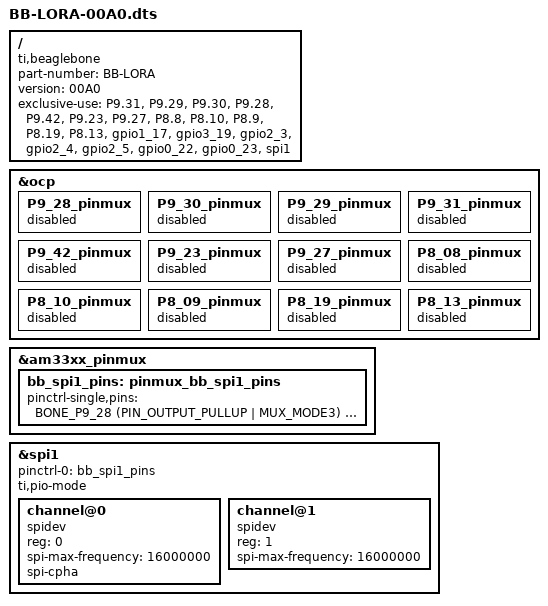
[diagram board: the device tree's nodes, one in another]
/*
 * 2018 Copyright (c) Seeed Technology Inc.  All right reserved.
 * Author:Junmin Fan <junmin.fan@seeed.cc>
 *
 * This program is free software; you can redistribute it and/or modify
 * it under the terms of the GNU General Public License version 2 as
 * published by the Free Software Foundation.
 */

/dts-v1/;
/plugin/;

#include <dt-bindings/board/am335x-bbw-bbb-base.h>
#include <dt-bindings/pinctrl/am33xx.h>

/ {
	compatible = "ti,beaglebone", "ti,beaglebone-black", "ti,beaglebone-green";

	/* identification */
	part-number = "BB-LORA";
	version = "00A0";

	/* state the resources this cape uses */
	exclusive-use =
		/* the pin header uses */
		"P9.31",	/* spi1_sclk */
		"P9.29",	/* spi1_d0 */
		"P9.30",	/* spi1_d1 */
		"P9.28",	/* spi1_cs0 */
		"P9.42",	/* spi1_cs1 */
		"P9.23",	/* lora reset gpio1_17 */
		"P9.27",	/* lora GPIO0 gpio3_19 */
		"P8.8",	    /* lora GPIO1 gpio2_3 */
		"P8.10",	/* lora GPIO2 gpio2_4 */
		"P8.9",	    /* lora GPIO3 gpio2_5 */
		"P8.19",	/* lora GPIO4 gpio0_22 */
		"P8.13",	/* lora GPS_PPS gpio0_23 */

		/* the hardware ip uses */
		"gpio1_17",
		"gpio3_19",
		"gpio2_3",
		"gpio2_4",
		"gpio2_5",
		"gpio0_22",
		"gpio0_23",
		"spi1";

	/*
	 * Free up the pins used by the cape from the pinmux helpers.
	 */
	fragment@0 {
		target = <&ocp>;
		__overlay__ {
			P9_28_pinmux { status = "disabled"; };	/* spi1_cs0 */
			P9_30_pinmux { status = "disabled"; };	/* spi1_d1 */
			P9_29_pinmux { status = "disabled"; };	/* spi1_d0 */
			P9_31_pinmux { status = "disabled"; };	/* spi1_sclk */
			P9_42_pinmux { status = "disabled"; };	/* spi1_cs1 */
			P9_23_pinmux { status = "disabled"; };	/* lora reset gpio1_17 */
			P9_27_pinmux { status = "disabled"; };	/* lora GPIO0 gpio3_19 */
			P8_08_pinmux { status = "disabled"; };	/* lora GPIO1 gpio2_3 */
			P8_10_pinmux { status = "disabled"; };	/* lora GPIO2 gpio2_4 */
			P8_09_pinmux { status = "disabled"; };	/* lora GPIO3 gpio2_5 */
			P8_19_pinmux { status = "disabled"; };	/* lora GPIO4 gpio0_22 */
			P8_13_pinmux { status = "disabled"; };	/* lora GPS_PPS gpio0_23 */
		};
	};

	fragment@1 {
		target = <&am33xx_pinmux>;
		__overlay__ {
			/* default state has all gpios released and mode set to uart1 */
			bb_spi1_pins: pinmux_bb_spi1_pins {
				pinctrl-single,pins = <
					BONE_P9_28 (PIN_OUTPUT_PULLUP | MUX_MODE3)	 /* mcasp0_ahclkr.spi1_cs0, OUTPUT_PULLUP | MODE3  */
					BONE_P9_30 (PIN_OUTPUT_PULLUP | MUX_MODE3)	 /* mcasp0_axr0.spi1_d1, OUTPUT_PULLUP | MODE3  */
					BONE_P9_29 (PIN_INPUT_PULLUP | MUX_MODE3)	 /* mcasp0_fsx.spi1_d0, INPUT_PULLUP | MODE3  */
					BONE_P9_31 (PIN_INPUT_PULLUP | MUX_MODE3)	 /* mcasp0_aclkx.spi1_sclk, INPUT_PULLUP | MODE3  */
					BONE_P9_23 (PIN_OUTPUT_PULLDOWN | MUX_MODE7) /* lora reset gpio1_17  */
					BONE_P9_27 (PIN_OUTPUT_PULLDOWN | MUX_MODE7) /* lora GPIO0 gpio3_19  */
					BONE_P8_08 (PIN_OUTPUT_PULLDOWN | MUX_MODE7) /* lora GPIO1 gpio2_3  */
					BONE_P8_10 (PIN_OUTPUT_PULLDOWN | MUX_MODE7) /* lora GPIO2 gpio2_4  */
					BONE_P8_09 (PIN_OUTPUT_PULLDOWN | MUX_MODE7) /* lora GPIO3 gpio2_5  */
					BONE_P8_19 (PIN_OUTPUT_PULLDOWN | MUX_MODE7) /* lora GPIO4 gpio0_22  */
					BONE_P8_13 (PIN_OUTPUT_PULLDOWN | MUX_MODE7) /* lora GPS_PPS gpio0_23  */
					0x164 0x12   /* eCAP0_in_PWM0_out.spi1_cs1 OUTPUT_PULLUP | MODE2  */
				>;
			};
		};
	};

	fragment@2 {
		target = <&spi1>;
		__overlay__ {
			#address-cells = <1>;
			#size-cells = <0>;

			status = "okay";
			pinctrl-names = "default";
			pinctrl-0 = <&bb_spi1_pins>;
			ti,pio-mode; /* disable dma when used as an overlay, dma gets stuck at 160 bits... */

			channel@0 {
				#address-cells = <1>;
				#size-cells = <0>;

				compatible = "spidev";

				reg = <0>;
				spi-max-frequency = <16000000>;
				spi-cpha;
			};

			channel@1 {
				#address-cells = <1>;
				#size-cells = <0>;

				compatible = "spidev";

				reg = <1>;
				spi-max-frequency = <16000000>;
			};
		};
	};
};
